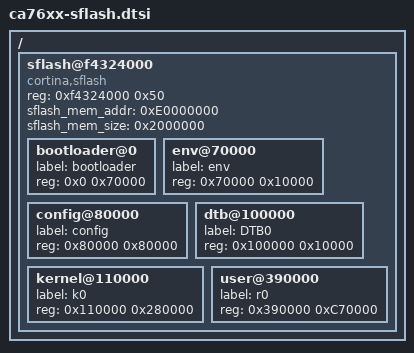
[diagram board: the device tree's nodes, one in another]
/*
 * Copyright (c) 2015-2017, Cortina Access. All rights reserved.
 *
 * Redistribution and use in source and binary forms, with or without
 * modification, are permitted provided that the following conditions are met:
 *
 * Redistributions of source code must retain the above copyright notice, this
 * list of conditions and the following disclaimer.
 *
 * Redistributions in binary form must reproduce the above copyright notice,
 * this list of conditions and the following disclaimer in the documentation
 * and/or other materials provided with the distribution.
 *
 * THIS SOFTWARE IS PROVIDED BY THE COPYRIGHT HOLDERS AND CONTRIBUTORS "AS IS"
 * AND ANY EXPRESS OR IMPLIED WARRANTIES, INCLUDING, BUT NOT LIMITED TO, THE
 * IMPLIED WARRANTIES OF MERCHANTABILITY AND FITNESS FOR A PARTICULAR PURPOSE
 * ARE DISCLAIMED. IN NO EVENT SHALL THE COPYRIGHT HOLDER OR CONTRIBUTORS BE
 * LIABLE FOR ANY DIRECT, INDIRECT, INCIDENTAL, SPECIAL, EXEMPLARY, OR
 * CONSEQUENTIAL DAMAGES (INCLUDING, BUT NOT LIMITED TO, PROCUREMENT OF
 * SUBSTITUTE GOODS OR SERVICES; LOSS OF USE, DATA, OR PROFITS; OR BUSINESS
 * INTERRUPTION) HOWEVER CAUSED AND ON ANY THEORY OF LIABILITY, WHETHER IN
 * CONTRACT, STRICT LIABILITY, OR TORT (INCLUDING NEGLIGENCE OR OTHERWISE)
 * ARISING IN ANY WAY OUT OF THE USE OF THIS SOFTWARE, EVEN IF ADVISED OF THE
 * POSSIBILITY OF SUCH DAMAGE.
 */

/ {
	sflash@f4324000 {
		#address-cells = <1>;
		#size-cells = <1>;
		compatible = "cortina,sflash";
		reg = <0xf4324000 0x50>;
		sflash_mem_addr = <0xE0000000>;
		sflash_mem_size = <0x2000000>;

		bootloader@0 {
			label = "bootloader";
			reg = <0x0 0x70000>;
		};

		env@70000 {
			label = "env";
			reg = <0x70000 0x10000>;
		};

		config@80000 {
			label = "config";
			reg = <0x80000 0x80000>;
		};

		dtb@100000 {
			label = "DTB0";
			reg = <0x100000 0x10000>;
		};

		kernel@110000 {
			label = "k0";
			reg = <0x110000 0x280000>;
		};

		user@390000 {
			label = "r0";
			reg = <0x390000 0xC70000>;
		};
	};
};

